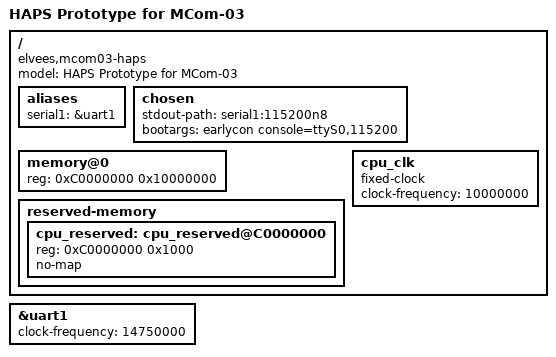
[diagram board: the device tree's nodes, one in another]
// SPDX-License-Identifier: GPL-2.0
/*
 * Copyright 2019 RnD Center "ELVEES", JSC
 *
 * This program is free software; you can redistribute it and/or modify
 * it under the terms of the GNU General Public License as published by
 * the Free Software Foundation; either version 2 of the License, or
 * (at your option) any later version.
 */

/dts-v1/;

#include "mcom03.dtsi"

/ {
	model = "HAPS Prototype for MCom-03";
	compatible = "elvees,mcom03-haps";

	aliases {
		serial1 = &uart1;
	};

	chosen {
		stdout-path = "serial1:115200n8";
		bootargs = "earlycon console=ttyS0,115200";
	};

	memory@0 {
		device_type = "memory";
		reg = <0xC0000000 0x10000000>; /* 256 MiB */
	};

	reserved-memory {
		#address-cells = <1>;
		#size-cells = <1>;
		ranges;

		cpu_reserved: cpu_reserved@C0000000 {
			reg = <0xC0000000 0x1000>;
			no-map;
		};
	};

	cpu_clk: cpu_clk {
		#clock-cells = <0>;
		compatible = "fixed-clock";
		clock-frequency = <10000000>;
	};
};

&uart1 {
	status = "okay";
	clock-frequency = <14750000>;
};
